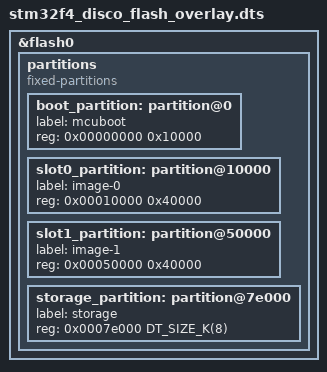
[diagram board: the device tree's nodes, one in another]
&flash0 {
	partitions {
		compatible = "fixed-partitions";
		#address-cells = <1>;
		#size-cells = <1>;

		boot_partition: partition@0 {
			label = "mcuboot";
			reg = <0x00000000 0x10000>;
		};
		slot0_partition: partition@10000 {
			label = "image-0";
			reg = <0x00010000 0x40000>;
		};
		slot1_partition: partition@50000 {
			label = "image-1";
			reg = <0x00050000 0x40000>;
		};
		storage_partition: partition@7e000 {
			label = "storage";
			reg = <0x0007e000 DT_SIZE_K(8)>;
		};
	};
};
